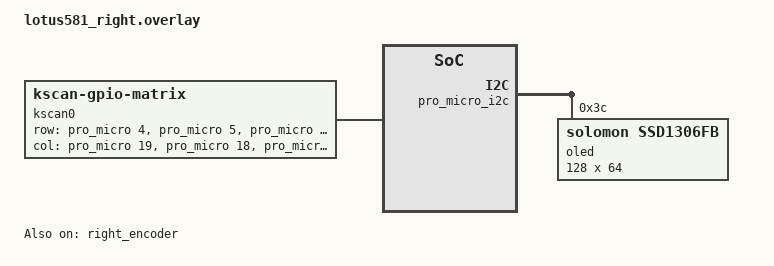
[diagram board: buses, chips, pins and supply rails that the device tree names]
/*
 * Copyright (c) 2022 The ZMK Contributors
 *
 * SPDX-License-Identifier: MIT
 */

#include "lotus581.dtsi"

/ {
    chosen {
        zmk,kscan = &kscan0;
    };

    kscan0: kscan {
        compatible = "zmk,kscan-gpio-matrix";
        wakeup-source;

        diode-direction = "col2row";
        row-gpios
            = <&pro_micro 4 (GPIO_ACTIVE_HIGH | GPIO_PULL_DOWN)>
            , <&pro_micro 5 (GPIO_ACTIVE_HIGH | GPIO_PULL_DOWN)>
            , <&pro_micro 6 (GPIO_ACTIVE_HIGH | GPIO_PULL_DOWN)>
            , <&pro_micro 7 (GPIO_ACTIVE_HIGH | GPIO_PULL_DOWN)>
            , <&pro_micro 8 (GPIO_ACTIVE_HIGH | GPIO_PULL_DOWN)>
            ;
        col-gpios
        = <&pro_micro 19 GPIO_ACTIVE_HIGH>
        , <&pro_micro 18 GPIO_ACTIVE_HIGH>
        , <&pro_micro 10 GPIO_ACTIVE_HIGH>
        , <&pro_micro 14 GPIO_ACTIVE_HIGH>
        , <&pro_micro 16 GPIO_ACTIVE_HIGH>
        , <&pro_micro 15 GPIO_ACTIVE_HIGH>
        ;
    };
};

&right_encoder {
    status = "okay";
    a-gpios = <&pro_micro 20 (GPIO_ACTIVE_HIGH | GPIO_PULL_UP)>;
    b-gpios = <&pro_micro 21 (GPIO_ACTIVE_HIGH | GPIO_PULL_UP)>;
};

&default_transform {
    col-offset = <6>;
};

&physical_layout0 {
    transform = <&default_transform>;
};

&pro_micro_i2c {
    status = "okay";

    oled: ssd1306@3c {
        compatible = "solomon,ssd1306fb";
        reg = <0x3c>;
        width = <128>;
        height = <64>;
        segment-offset = <0>;
        page-offset = <0>;
        display-offset = <0>;
        multiplex-ratio = <63>;
        prechargep = <0xF1>;
        /delete-property/ segment-remap;
    };
};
